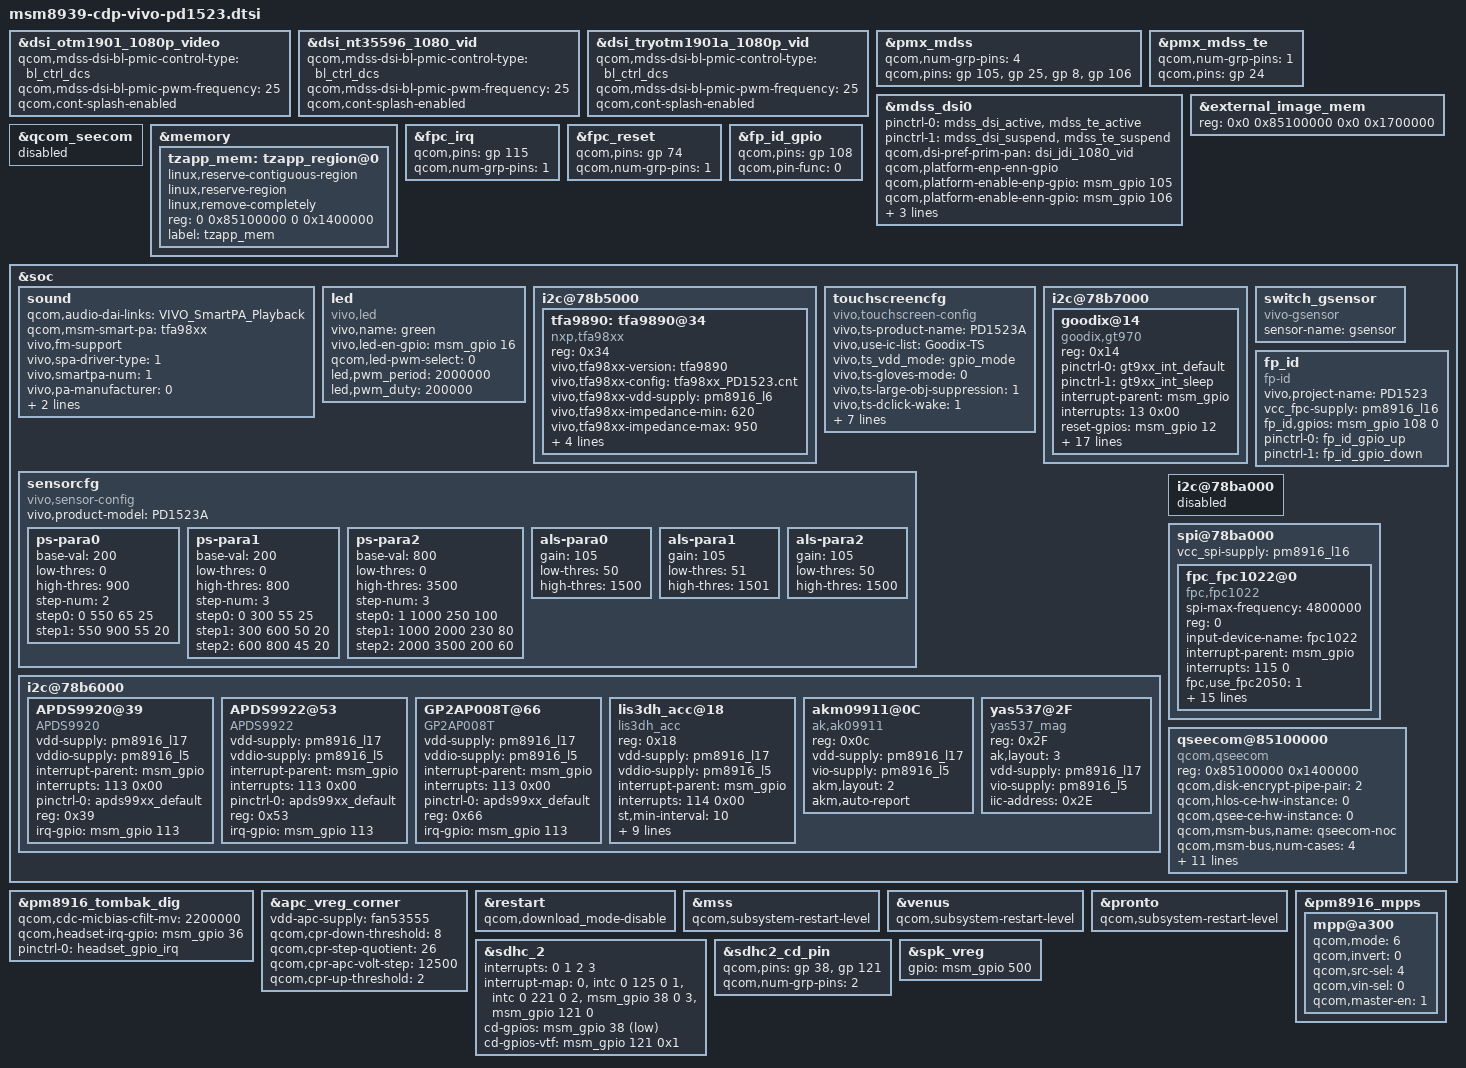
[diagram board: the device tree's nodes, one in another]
/* Copyright (c) 2014-2015, The Linux Foundation. All rights reserved.
 *
 * This program is free software; you can redistribute it and/or modify
 * it under the terms of the GNU General Public License version 2 and
 * only version 2 as published by the Free Software Foundation.
 *
 * This program is distributed in the hope that it will be useful,
 * but WITHOUT ANY WARRANTY; without even the implied warranty of
 * MERCHANTABILITY or FITNESS FOR A PARTICULAR PURPOSE.  See the
 * GNU General Public License for more details.
 */
#include "dsi-panel-otm1901-1080p-video.dtsi"
#include "dsi-panel-nt35596-1080p-video.dtsi"
#include "dsi-panel-tryotm1901a-1080p-video.dtsi"

#include "msm8939-camera-sensor-cdp-vivo-pd1523.dtsi"
 &dsi_otm1901_1080p_video {
	qcom,mdss-dsi-bl-pmic-control-type = "bl_ctrl_dcs";
	qcom,mdss-dsi-bl-pmic-pwm-frequency = <25>;
	//qcom,mdss-dsi-bl-pmic-bank-select = <0>;
	//qcom,mdss-dsi-pwm-gpio = <&pm8916_mpps 4 0>;
	qcom,cont-splash-enabled;
};

 &dsi_nt35596_1080_vid {
	qcom,mdss-dsi-bl-pmic-control-type = "bl_ctrl_dcs";
	qcom,mdss-dsi-bl-pmic-pwm-frequency = <25>;
	//qcom,mdss-dsi-bl-pmic-bank-select = <0>;
	//qcom,mdss-dsi-pwm-gpio = <&pm8916_mpps 4 0>;
	qcom,cont-splash-enabled;
};

 &dsi_tryotm1901a_1080p_vid {
	qcom,mdss-dsi-bl-pmic-control-type = "bl_ctrl_dcs";
	qcom,mdss-dsi-bl-pmic-pwm-frequency = <25>;
	//qcom,mdss-dsi-bl-pmic-bank-select = <0>;
	//qcom,mdss-dsi-pwm-gpio = <&pm8916_mpps 4 0>;
	qcom,cont-splash-enabled;
};


&pmx_mdss {
	qcom,num-grp-pins = <4>;
	qcom,pins = <&gp 105>, <&gp 25>, <&gp 8>, <&gp 106>;
	//qcom,pins = <&gp 105>, <&gp 25>, <&gp 8>, <&gp 106>, <&gp 1>;
};

&pmx_mdss_te {
	qcom,num-grp-pins = <1>;
	qcom,pins = <&gp 24>;
};
&mdss_dsi0 {
	pinctrl-names = "mdss_default", "mdss_sleep";
	pinctrl-0 = <&mdss_dsi_active &mdss_te_active>;
	pinctrl-1 = <&mdss_dsi_suspend &mdss_te_suspend>;
	qcom,dsi-pref-prim-pan = <&dsi_jdi_1080_vid>;
    
    qcom,platform-enp-enn-gpio;
    qcom,platform-enable-enp-gpio = <&msm_gpio 105 0>;
    qcom,platform-enable-enn-gpio = <&msm_gpio 106 0>;
	qcom,platform-reset-gpio = <&msm_gpio 25 0>;
	qcom,platform-bklight-en-gpio = <&msm_gpio 8 0>;
	qcom,platform-spotlight-en-gpio = <&msm_gpio 1 0>;
};

&external_image_mem{
	reg = <0x0 0x85100000 0x0 0x1700000>;
};
&qcom_seecom {
	status = "disabled";
};
&memory {
		tzapp_mem: tzapp_region@0 {
			linux,reserve-contiguous-region;
			linux,reserve-region;
			linux,remove-completely;
			reg = <0 0x85100000 0 0x1400000>;
			label = "tzapp_mem";
		};
};

&fpc_irq {
			qcom,pins = <&gp 115>;
			qcom,num-grp-pins = <1>;
};

&fpc_reset {
			qcom,pins = <&gp 74>;
			qcom,num-grp-pins = <1>;
};

&fp_id_gpio{
			qcom,pins = <&gp 108>;
			qcom,pin-func = <0>;
};

&soc {
	sound {
		qcom,audio-dai-links = 
			"VIVO_SmartPA_Playback";
		qcom,msm-smart-pa = "tfa98xx";
		/* Sound card info */
		vivo,fm-support;
		vivo,spa-driver-type = <1>;
		vivo,smartpa-num = <1>;
		vivo,pa-manufacturer = <0>;
		vivo,fm-pcm-hp = <5>;
		vivo,fm-pcm-spk = <42>;
	};
	led {
		compatible = "vivo,led";
		vivo,name = "green";
		vivo,led-en-gpio=<&msm_gpio 16 0>;
		//qcom,led-pwm-gpio = <&pm8916_mpps 4 0>;
		
		qcom,led-pwm-select = <0>;
		led,pwm_period=<2000000>;
		led,pwm_duty=<200000>;
	};

	i2c@78b5000 {/* audio smart pa*/
		status="ok";
		tfa9890: tfa9890@34 {
			compatible = "nxp,tfa98xx";
			reg = <0x34>;
			vivo,tfa98xx-version = "tfa9890";
			vivo,tfa98xx-config = "tfa98xx_PD1523.cnt";
			vivo,tfa98xx-vdd-supply = <&pm8916_l6>;
			vivo,tfa98xx-impedance-min = <620>;
			vivo,tfa98xx-impedance-max = <950>;
			vivo,tfa98xx-frequency-min = <650>;
			vivo,tfa98xx-frequency-max = <850>;
			qcom,tfa98xx-rst-gpio = <&msm_gpio 9 0>;
			qcom,tfa98xx-eint-gpio = <&msm_gpio 120 0>;
		};
	};
	touchscreencfg { /* vivo ts configure */
	   compatible = "vivo,touchscreen-config";
	   vivo,ts-product-name="PD1523A";
	   vivo,use-ic-list="Goodix-TS";
	   vivo,ts_vdd_mode="gpio_mode"; /*regulator_mode or gpio_mode*/
	   
	   /*----- function set BEG ---- */
	   vivo,ts-gloves-mode=<0>;
	   vivo,ts-large-obj-suppression=<1>;
	   vivo,ts-dclick-wake=<1>;
	   vivo,ts-gesture-mode=<1>; /*1=sold in native,2=sold in abroad,3...etc=for custom extensive*/
	   vivo,ts-custom-gesture=<0>;
	   vivo,ts-module-id-methods=<0>;/*0=by IC id,1=gpio,2=by LCD ID 3=...etc=for custom extensive*/
	   vivo,ts-fw-upgrade-lcd-referrence=<0>;
	   vivo,ts-anti-esd=<1>;
	   vivo,ts-charger-conn-judge=<1>;
	   vivo,ts-module-smt-mode=<1>; /* 0=COB,1=COF */
	   /*----- function set END ---- */

	};
	i2c@78b7000 { /* BLSP1 QUP5 */
        status = "ok";
		goodix@14 { //gt970L
			compatible = "goodix,gt970";
			reg = <0x14>;
			/* pins used by touchscreen */
			pinctrl-names = "gt9xx_int_default","gt9xx_int_suspend";
            		pinctrl-0 = <&gt9xx_int_default>;
            		pinctrl-1 = <&gt9xx_int_sleep>;
			interrupt-parent = <&msm_gpio>;
			interrupts = <13 0x00>;
			reset-gpios = <&msm_gpio 12 0x00>;
			interrupt-gpios = <&msm_gpio 13 0x00>;
            //vcc_i2c-supply = <&pm8916_l6>;
            //vdd-supply = <&pm8916_l16>;/* <&tp_power>;*/
			goodix,vdd-gpio = <&pm8916_gpios 3 0>;
			goodix,panel-coords = <0 0 1080 1920>;
			goodix,display-coords = <0 0 1080 1920>;
			goodix,button-map= <158 102 139>;
			goodix,family-id = <0x0>;
           		goodix,i2c-pull-up;
			goodix,cfg-data0 =    //jiemian
			[
				4C 38 04 FF 07 0A 34 D0 01 08 
				3C 08 50 32 30 35 00 00 37 13 
				10 01 00 14 14 26 14 8C 2E 0E 
				41 43 9D 09 9D 09 00 9A 33 11 
				00 00 00 00 00 00 00 08 0A A0 
				22 26 46 54 D0 02 8C 1E 00 04 
				B3 28 00 A4 2D 23 96 33 00 89 
				3A 00 7F 41 00 80 00 00 00 00 
				00 00 00 00 00 00 00 00 00 00 
				00 00 00 00 FF 01 00 00 00 00 
				00 00 00 00 00 0F 50 00 00 00 
				00 1E 1C 1A 18 16 14 12 10 0E 
				0C 0A 08 06 04 02 00 98 FB 28 
				AC 1E 1E 14 08 1E 96 00 DC 00 
				40 41 00 02 04 06 08 0A 0C 0F 
				10 12 13 14 16 18 1C 1D 1E 1F 
				20 21 22 24 26 28 29 2A 00 00 
				00 00 00 00 00 00 00 00 00 00 
				16 15 23 05 8E 01
			];                                         
			
			goodix,cfg-data2 =    //yeji
			[
				41 38 04 FF 07 0A 34 00 01 08 
				3C 05 50 32 33 35 00 00 37 13 
				10 01 00 14 14 26 14 8C 2E 0E 
				32 34 B8 08 B8 08 00 9A 33 11 
				00 00 00 00 00 03 64 08 0A 00 
				21 1E 5A 54 C0 02 BC 1E 00 04 
				B1 21 00 95 29 23 7C 34 00 6A 
				41 00 5D 51 00 5D 00 00 00 00 
				00 00 00 00 00 00 00 00 00 00 
				00 00 00 00 FF 01 00 00 00 00 
				00 00 00 00 00 0F 50 00 00 00 
				00 1E 1C 1A 18 16 14 12 10 0E 
				0C 0A 08 06 04 02 00 00 00 00 
				00 00 00 00 00 00 00 00 DC 00 
				50 00 00 02 04 06 08 0A 0C 0F 
				10 12 13 14 16 18 1C 1D 1E 1F 
				20 21 22 24 26 28 29 2A 00 00 
				00 00 00 00 00 00 00 00 00 00 
				00 00 00 00 DA 01
			];              
			
			goodix,cfg-data3 =    //lansi
			[
				41 38 04 FF 07 0A 34 00 01 08 
				3C 05 50 32 33 35 00 00 37 13 
				10 01 00 14 14 26 14 8C 2E 0E 
				32 34 B8 08 B8 08 00 9A 33 11 
				00 00 00 00 00 03 64 08 0A 00 
				21 1E 5A 54 C0 02 BC 1E 00 04 
				B1 21 00 95 29 23 7C 34 00 6A 
				41 00 5D 51 00 5D 00 00 00 00 
				00 00 00 00 00 00 00 00 00 00 
				00 00 00 00 FF 01 00 00 00 00 
				00 00 00 00 00 0F 50 00 00 00 
				00 1E 1C 1A 18 16 14 12 10 0E 
				0C 0A 08 06 04 02 00 00 00 00 
				00 00 00 00 00 00 00 00 DC 00 
				50 00 00 02 04 06 08 0A 0C 0F 
				10 12 13 14 16 18 1C 1D 1E 1F 
				20 21 22 24 26 28 29 2A 00 00 
				00 00 00 00 00 00 00 00 00 00 
				00 00 00 00 DA 01
			];                                   
				
			ts-suspend-resume=<0>;
			ts-fixed-key-type=<1>; /*0=0d,1=2d */
			
			/*--virtualkeys: EV_KEY:KEY_MENU:cx:cy:w:h:EV_KEY:KEY_HOMEPAGE:cx:cy:w:h:EV_KEY:KEY_BACK:cx:cy:w:h--*/
			ts-virt-key="0x01:139:208:2038:140:100:0x01:251:340:2038:95:100:0x01:172:548:2038:140:100:0x01:251:720:2038:100:100:0x01:158:890:2038:140:100";
		};
	
	};
	sensorcfg {
		compatible = "vivo,sensor-config";
		vivo,product-model = "PD1523A";
		ps-para0 {
			base-val = <200>;
			low-thres = <0>;
			high-thres = <900>;
			step-num = <2>;
			step0 = <0 550 65 25>;
			step1 = <550 900 55 20>;
		};
             /*for test,ignore it*/
		ps-para1 {
			base-val = <200>;
			low-thres = <0>;
			high-thres = <800>;
			step-num = <3>;
			step0 = <0 300 55 25>;
			step1 = <300 600 50 20>;
			step2 = <600 800 45 20>;
		};
		ps-para2 {
			base-val = <800>;
			low-thres = <0>;
			high-thres = <3500>;
			step-num = <3>;
			step0 = <1 1000 250 100>;
			step1 = <1000 2000 230 80>;
			step2 = <2000 3500 200 60>;
		};
		als-para0 {
			gain = <105>;
			low-thres = <50>;
			high-thres = <1500>;
		};
             /*for test,ignore it*/
		als-para1 {
			gain = <105>;
			low-thres = <51>;
			high-thres = <1501>;
		};
		als-para2 {
			gain = <105>;
			low-thres = <50>;
			high-thres = <1500>;
		};
	};
	switch_gsensor {
		  compatible = "vivo-gsensor";
		  sensor-name = "gsensor";
		/*  sensor,gpio-irq = <&msm_gpio 21 0x00>;  */
	};
	i2c@78b6000 { /* BLSP1 QUP2 */
		APDS9920@39 {
			compatible = "APDS9920";
			vdd-supply = <&pm8916_l17>;
			vddio-supply = <&pm8916_l5>;
			interrupt-parent = <&msm_gpio>;
			interrupts = <113 0x00>;
			pinctrl-names = "default";
			pinctrl-0 = <&apds99xx_default>;
			reg = <0x39>;
			irq-gpio = <&msm_gpio 113 0x00>;
		};	
		APDS9922@53 {
			compatible = "APDS9922";
			vdd-supply = <&pm8916_l17>;
			vddio-supply = <&pm8916_l5>;
			interrupt-parent = <&msm_gpio>;
			interrupts = <113 0x00>;
			pinctrl-names = "default";
			pinctrl-0 = <&apds99xx_default>;
			reg = <0x53>;
			irq-gpio = <&msm_gpio 113 0x00>;
		};
        GP2AP008T@66 {
			compatible = "GP2AP008T";
			vdd-supply = <&pm8916_l17>;
			vddio-supply = <&pm8916_l5>;
			interrupt-parent = <&msm_gpio>;
			interrupts = <113 0x00>;
			pinctrl-names = "default";
			pinctrl-0 = <&apds99xx_default>;
			reg = <0x66>;
			irq-gpio = <&msm_gpio 113 0x00>;
		};			
		lis3dh_acc@18 {
			compatible = "lis3dh_acc";
			reg = <0x18>;
			vdd-supply = <&pm8916_l17>;
			vddio-supply = <&pm8916_l5>;
			interrupt-parent = <&msm_gpio>;
			interrupts = <114 0x00>;
			st,min-interval = <10>;
			st,init-interval = <200>;
			st,axis-map-x = <1>;
			st,axis-map-y = <0>;
			st,axis-map-z = <2>;
			st,g-range = <2>;
			st,negate-x = <1>;
			st,negate-y = <0>;
			st,negate-z = <0>;
            sensor,gpio-irq = <&msm_gpio 114 0x00>;			
		};
	    akm09911@0C{
		    compatible = "ak,ak09911";
		    reg = <0x0c>;
		    vdd-supply = <&pm8916_l17>;
		    vio-supply = <&pm8916_l5>;
		    akm,layout = <2>;
		    akm,auto-report;
	    };
	    yas537@2F {
			compatible = "yas537_mag";
			reg = <0x2F>;
			ak,layout =<3>;
			vdd-supply = <&pm8916_l17>;
			vio-supply = <&pm8916_l5>;
			iic-address=<0x2E>;
		};
	};
	
	fp_id:fp_id {
		compatible = "fp-id";
		status = "ok";
		vivo,project-name = "PD1523";
		vcc_fpc-supply  = <&pm8916_l16>;
		fp_id,gpios = <&msm_gpio 108 0>;
		pinctrl-names = "fp_gpio_pull_up",
						"fp_gpio_pull_down";
		pinctrl-0 = <&fp_id_gpio_up>;
		pinctrl-1 = <&fp_id_gpio_down>;
	};
	i2c@78ba000 { /* BLSP1 QUP6 */
		status = "disabled";
	};
	// add by gongyulong for fingerprint
	spi@78ba000 {
		status = "ok";
		vcc_spi-supply  = <&pm8916_l16>;
	    fpc_fpc1022@0 {
	    compatible = "fpc,fpc1022";
		spi-max-frequency = <4800000>;
	    reg = <0>;
	    input-device-name = "fpc1022";
	    interrupt-parent = <&msm_gpio>;
	    interrupts = <115 0>;

	    fpc,use_fpc2050 = <1>;
		fpc,enable-on-boot;
		fpc,enable-wakeup;
		fpc,event-type = <4>;
		fpc,event-code = <4>;
		spi-qup-id = <6>;
		vcc_spi-supply  = <&pm8916_l16>;
		vdd_ana-supply  = <&pm8916_l16>;
		vdd_io-supply   = <&pm8916_l16>;

	    fpc,gpio_reset = <&msm_gpio 74 0x00>;
		fpc,gpio_irq = <&msm_gpio 115 0x00>;

		clock-names = "iface_clk", "core_clk";
		clocks = <&clock_gcc clk_gcc_blsp1_ahb_clk>,
				<&clock_gcc clk_gcc_blsp1_qup6_spi_apps_clk>;

		pinctrl-names = "fpc1020_irq_active",
				"fpc1020_reset_active",
				"fpc1020_reset_reset";
		pinctrl-0 = <&fpc_irq_active>;
		pinctrl-1 = <&fpc_reset_active>;
		pinctrl-2 = <&fpc_reset_reset>;
		};
	};

	qseecom@85100000 {
		compatible = "qcom,qseecom";
		reg = <0x85100000 0x1400000>;
		reg-names = "secapp-region";
		qcom,disk-encrypt-pipe-pair = <2>;
		qcom,hlos-ce-hw-instance = <0>;
		qcom,qsee-ce-hw-instance = <0>;
		qcom,msm-bus,name = "qseecom-noc";
		qcom,msm-bus,num-cases = <4>;
		qcom,msm-bus,num-paths = <1>;
		qcom,support-bus-scaling;
		qcom,support-fde;
		qcom,msm-bus,vectors-KBps =
				<55 512 0 0>,
				<55 512 0 0>,
				<55 512 120000 1200000>,
				<55 512 393600 3936000>;
		clocks = <&clock_gcc clk_crypto_clk_src>,
			 <&clock_gcc clk_gcc_crypto_clk>,
			 <&clock_gcc clk_gcc_crypto_ahb_clk>,
			 <&clock_gcc clk_gcc_crypto_axi_clk>;
		clock-names = "core_clk_src", "core_clk",
				"iface_clk", "bus_clk";
		status = "ok";
		qcom,ce-opp-freq = <100000000>;
	}; 
};

&pm8916_tombak_dig{
		qcom,cdc-micbias-cfilt-mv = <2200000>;
		qcom,headset-irq-gpio = <&msm_gpio 36 0>;
		pinctrl-names = "headset_gpio_irq";
		pinctrl-0 =  <&headset_gpio_irq>;
	};

&apc_vreg_corner {
		vdd-apc-supply = <&fan53555>;
		 qcom,cpr-down-threshold = <8>;
		 qcom,cpr-step-quotient = <26>;
		 qcom,cpr-apc-volt-step = <12500>;
		 qcom,cpr-up-threshold = <2>; 
};
&restart {
	qcom,download_mode-disable;
};
&mss {
	qcom,subsystem-restart-level;
};
&venus {
	qcom,subsystem-restart-level;
};
&pronto {
	qcom,subsystem-restart-level;
};

&pm8916_mpps {
	mpp@a300 { /* MPP 4 */
		/* Backlight PWM */
		qcom,mode = <6>;		/* Digital output */
		qcom,invert = <0>;		/* Disable invert */
		qcom,src-sel = <4>;		/* DTEST1 */
		qcom,vin-sel = <0>;		/* VPH_PWR */
		qcom,master-en = <1>;		/* Enable MPP */
	};
};

/* add for VTF */
&sdhc_2 {
    interrupts = <0 1 2 3>;
    interrupt-map = <0 &intc 0 125 0
            1 &intc 0 221 0
            2 &msm_gpio 38 0
            3 &msm_gpio 121 0>;
    cd-gpios = <&msm_gpio 38 0x1>;
    cd-gpios-vtf = <&msm_gpio 121 0x1>;
};

&sdhc2_cd_pin {
            qcom,pins = <&gp 38>, <&gp 121>;
            qcom,num-grp-pins = <2>;
};



/* this module occupeis gpio of TF card. so overwrite it. */
&spk_vreg {
    gpio = <&msm_gpio 500 0>;
};
/* add end */
